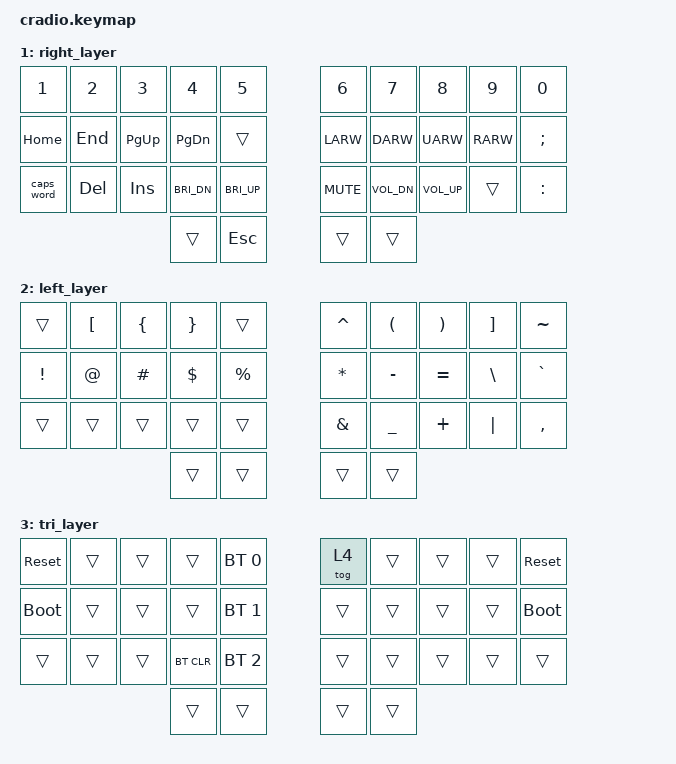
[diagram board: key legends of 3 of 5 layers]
// Copyright (c) 2022 The ZMK Contributors
// SPDX-License-Identifier: MIT

#include <behaviors.dtsi>
#include <dt-bindings/zmk/keys.h>
#include <dt-bindings/zmk/bt.h>

// Home row mods macro
#define HRML(k1,k2,k3,k4) &ht LSHFT k1  &ht LALT k2  &ht LCTRL k3  &ht LGUI k4
#define HRMR(k1,k2,k3,k4) &ht RGUI k1  &ht RCTRL k2  &ht RALT k3  &ht RSHFT k4

/ {
    behaviors {
        ht: hold_tap {
            label = "hold_tap";
            compatible = "zmk,behavior-hold-tap";
            #binding-cells = <2>;
            flavor = "tap-preferred";
            tapping-term-ms = <220>;
            quick-tap-ms = <150>;
            global-quick-tap;
            bindings = <&kp>, <&kp>;
        };
    };

    conditional_layers {
        compatible = "zmk,conditional-layers";
        tri_layer {
            if-layers = <1 2>;
            then-layer = <3>;
        };
    };

    keymap {
        compatible = "zmk,keymap";
        default_layer {
            bindings = <
        //╭──────────┬──────────┬──────────┬──────────┬──────────╮   ╭──────────┬──────────┬──────────┬──────────┬──────────╮
        //│  Q       │  W       │  E       │  R       │  T       │   │  Y       │  U       │  I       │  O       │  P       │
            &kp Q      &kp W      &kp E      &kp R      &kp T          &kp Y      &kp U      &kp I      &kp O      &kp P
        //├──────────┼──────────┼──────────┼──────────┼──────────┤   ├──────────┼──────────┼──────────┼──────────┼──────────┤
        //│  A       │  S       │  D       │  F       │  G       │   │  H       │  J       │  K       │  L       │ ' "      │
            HRML(A,        S,         D,         F)     &kp G          &kp H      HRMR(J,        K,         L,        SQT)
        //├──────────┼──────────┼──────────┼──────────┼──────────┤   ├──────────┼──────────┼──────────┼──────────┼──────────┤
        //│  Z       │  X       │  C       │  V       │  B       │   │  N       │  M       │ , <      │ . >      │ / ?      │
            &kp Z      &kp X      &kp C      &kp V      &kp B          &kp N      &kp M      &kp COMMA  &kp DOT    &kp FSLH
        //╰──────────┴──────────┴──────────┼──────────┼──────────┤   ├──────────┼──────────┼──────────┴──────────┴──────────╯
                                            &lt 2 TAB   &kp ENTER     &kp SPACE  &lt 1 BSPC
        //                                 ╰──────────┴──────────╯   ╰──────────┴──────────╯
            >;
        };

        right_layer {
            bindings = <
        //╭──────────┬──────────┬──────────┬──────────┬──────────╮   ╭──────────┬──────────┬──────────┬──────────┬──────────╮
        //│ 1        │  2       │  3       │  4       │   5      │   │ 6        │ 7        │ 8        │ 9        │  0       │
            &kp N1     &kp N2     &kp N3     &kp N4     &kp N5         &kp N6     &kp N7     &kp N8     &kp N9     &kp N0
        //├──────────┼──────────┼──────────┼──────────┼──────────┤   ├──────────┼──────────┼──────────┼──────────┼──────────┤
        //│ DELETE   │  END     │ PAGE UP  │ PAGE DN  │          │   │ LEFT     │ DOWN     │ UP       │ RIGHT    │  ;       │
            &kp HOME   &kp END    &kp PG_UP  &kp PG_DN  &trans         &kp LARW   &kp DARW   &kp UARW   &kp RARW   &kp SEMI
        //├──────────┼──────────┼──────────┼──────────┼──────────┤   ├──────────┼──────────┼──────────┼──────────┼──────────┤
        //│ CAPS     │  DELETE  │  INSERT  │          │          │   │ F10      │ F11      │ F12      │          │  :       │
           &caps_word  &kp DEL    &kp INS &kp C_BRI_DN &kp C_BRI_UP &kp C_MUTE &kp C_VOL_DN &kp C_VOL_UP &trans   &kp COLON
        //╰──────────┴──────────┴──────────┼──────────┼──────────┤   ├──────────┼──────────┼──────────┴──────────┴──────────╯
                                             &trans     &kp ESC        &trans     &trans
        //                                 ╰──────────┴──────────╯   ╰──────────┴──────────╯
            >;
        };

        left_layer {
            bindings = <
        //╭──────────┬──────────┬──────────┬──────────┬──────────╮   ╭──────────┬──────────┬──────────┬──────────┬──────────╮
        //│          │  [       │  {       │  }       │          │   │  ^       │  (       │  )       │  ]       │  ~       │
            &trans     &kp LBKT   &kp LBRC   &kp RBRC   &trans         &kp CARET  &kp LPAR   &kp RPAR   &kp RBKT   &kp TILDE
        //├──────────┼──────────┼──────────┼──────────┼──────────┤   ├──────────┼──────────┼──────────┼──────────┼──────────┤
        //│  !       │  @       │  #       │  $       │  %       │   │  *       │  -       │  =       │  \       │  `       │
            &kp EXCL   &kp AT     &kp HASH   &kp DLLR   &kp PRCNT      &kp ASTRK  &kp MINUS  &kp EQUAL  &kp BSLH   &kp GRAVE
        //├──────────┼──────────┼──────────┼──────────┼──────────┤   ├──────────┼──────────┼──────────┼──────────┼──────────┤
        //│          │          │          │          │          │   │  &       │  _       │  +       │  │       │ , <      │
            &trans     &trans     &trans     &trans     &trans         &kp AMPS   &kp UNDER  &kp PLUS   &kp PIPE   &kp COMMA
        //╰──────────┴──────────┴──────────┼──────────┼──────────┤   ├──────────┼──────────┼──────────┴──────────┴──────────╯
                                             &trans     &trans         &trans     &trans
        //                                 ╰──────────┴──────────╯   ╰──────────┴──────────╯
            >;
        };

        tri_layer {
            bindings = <
        //╭──────────┬──────────┬──────────┬──────────┬──────────╮   ╭──────────┬──────────┬──────────┬──────────┬──────────╮
        //│ RESET    │          │          │          │PROFILE 0 │   │GRAPHITE  │          │          │          │  RESET   │
           &sys_reset  &trans     &trans     &trans    &bt BT_SEL 0    &tog 4     &trans     &trans     &trans    &sys_reset
        //├──────────┼──────────┼──────────┼──────────┼──────────┤   ├──────────┼──────────┼──────────┼──────────┼──────────┤
        //│BOOTLOADER│          │          │          │PROFILE 1 │   │          │          │          │          │BOOTLOADER│
          &bootloader  &trans     &trans     &trans    &bt BT_SEL 1    &trans     &trans     &trans     &trans    &bootloader
        //├──────────┼──────────┼──────────┼──────────┼──────────┤   ├──────────┼──────────┼──────────┼──────────┼──────────┤
        //│          │          │          │ CLEAR BT │PROFILE 2 │   │          │          │          │          │          │
            &trans     &trans     &trans    &bt BT_CLR &bt BT_SEL 2    &trans     &trans     &trans     &trans     &trans
        //╰──────────┴──────────┴──────────┼──────────┼──────────┤   ├──────────┼──────────┼──────────┴──────────┴──────────╯
                                             &trans     &trans         &trans     &trans
        //                                 ╰──────────┴──────────╯   ╰──────────┴──────────╯
            >;
        };

        graphite_layer {
            bindings = <
        //╭──────────┬──────────┬──────────┬──────────┬──────────╮   ╭──────────┬──────────┬──────────┬──────────┬──────────╮
        //│  B       │  L       │  D       │  W       │  Z       │   │  ' "     │  F       │  O       │  U       │  J       │
            &kp B      &kp L      &kp D      &kp W      &kp Z          &kp SQT      &kp F      &kp O      &kp U      &kp J
        //├──────────┼──────────┼──────────┼──────────┼──────────┤   ├──────────┼──────────┼──────────┼──────────┼──────────┤
        //│  N       │  R       │  T       │  S       │  G       │   │  Y       │  H       │  A       │  E       │   I      │
            HRML(N,        R,         R,         S)     &kp G          &kp Y      HRMR(H,        A,         E,        I)
        //├──────────┼──────────┼──────────┼──────────┼──────────┤   ├──────────┼──────────┼──────────┼──────────┼──────────┤
        //│  Q       │  X       │  M       │  C       │  V       │   │  K       │  P       │ . >      │ - _      │ / ?      │
            &kp Q      &kp X      &kp M      &kp C      &kp V          &kp K      &kp P      &kp DOT   &kp MINUS   &kp FSLH
        //╰──────────┴──────────┴──────────┼──────────┼──────────┤   ├──────────┼──────────┼──────────┴──────────┴──────────╯
                                            &lt 2 TAB   &kp ENTER     &kp SPACE  &lt 1 BSPC
        //                                 ╰──────────┴──────────╯   ╰──────────┴──────────╯
            >;
        };

    };
};
